# MKE14Z4 register map
Vendor: nxp.com; File version: 1.0
CPU: CM0PLUS r0p0, little endian, no MPU, no FPU, VTOR, 2 interrupt priority bits
Registers are 32-bit, read-write, reset 0x0 unless marked. A register's access mark holds for its fields unless they carry their own. Offsets are from the block's base; [hi:lo] are bit positions; {n}, {i} and the like mark numbered series.

## SIM — System Integration Module
Base 0x40048000; register names take the prefix SIM_
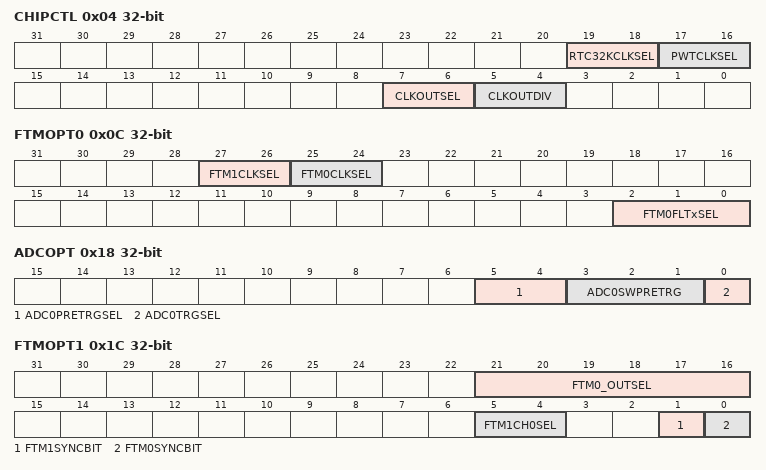
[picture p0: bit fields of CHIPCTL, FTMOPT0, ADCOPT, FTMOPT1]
0x04 CHIPCTL — Chip Control register
  [19:18] RTC32KCLKSEL — RTC 32K clock input select
    0=OSC32K (SOSC 32 kHZ high gain clock); 1=RTC_CLKIN
  [17:16] PWTCLKSEL — PWT clock source select
    0=TCLK0 (PWT alternative clock is from the TCLK0 pin.); 1=TCLK1 (PWT alternative clock is from the TCLK1 pin.); 2=TCLK2 (PWT alternative clock is from the TCLK2 pin.)
  [7:6] CLKOUTSEL — CLKOUT Select
    1=SCGCLKOUT (SCGCLKOUT(SIRC/FIRC/SOSC/LPFLL), see SCG_CLKOUTCNFG register.); 3=LPO (LPO clock (128 kHz))
  [5:4] CLKOUTDIV — CLKOUT divider ratio
    0=DIV1 (Divided by 1); 1=DIV2 (Divided by 2); 2=DIV4 (Divided by 4); 3=DIV8 (Divided by 8)
0x0C FTMOPT0 — FTM Option Register 0
  [27:26] FTM1CLKSEL — FTM1 External Clock Pin Select
    0=TCLK0 (FTM1 external clock driven by TCLK0 pin.); 1=TCLK1 (FTM1 external clock driven by TCLK1 pin.); 2=TCLK2 (FTM1 external clock driven by TCLK2 pin.); 3=NONE (No clock input)
  [25:24] FTM0CLKSEL — FTM0 External Clock Pin Select
    0=TCLK0 (FTM0 external clock driven by TCLK0 pin.); 1=TCLK1 (FTM0 external clock driven by TCLK1 pin.); 2=TCLK2 (FTM0 external clock driven by TCLK2 pin.); 3=NONE (No clock input)
  [2:0] FTM0FLTxSEL — FTM0 Fault x Select
0x18 ADCOPT — ADC Options Register
  [5:4] ADC0PRETRGSEL — ADC0 pre-trigger source select
    0=PDB (PDB output); 1=TRGMUX (TRGMUX output); 2=SOFTWR (ADC0 software pre-trigger)
  [3:1] ADC0SWPRETRG — ADC0 software pre-trigger sources
    0=DISABLED (software pre-trigger disabled); {v}=PRETR{v-4} (software pre-trigger {v-4}) (v=4..7)
  [0] ADC0TRGSEL — ADC0 trigger source select
    0=PDB (PDB output); 1=TRGMUX (TRGMUX output)
0x1C FTMOPT1 — FTM Option Register 1
  [21:16] FTM0_OUTSEL — FTM0 channel modulation select with FTM1_CH1
    0=NONE (No modulation with FTM1_CH1); 1=FTM1CH1 (Modulation with FTM1_CH1)
  [5:4] FTM1CH0SEL — FTM1 CH0 Select
    0=FTM1CH0 (FTM1_CH0 input); 1=CMP0 (CMP0 output)
  [1] FTM1SYNCBIT
    0=NONE (No effect.); 1=FTM1 (Write 1 to assert the TRIG1 input to FTM1. Software must clear this bit to allow other trigger sources to assert.)
  [0] FTM0SYNCBIT
    0=NONE (No effect.); 1=FTM0 (Write 1 to assert the TRIG1 input to FTM0. Software must clear this bit to allow other trigger sources to assert.)
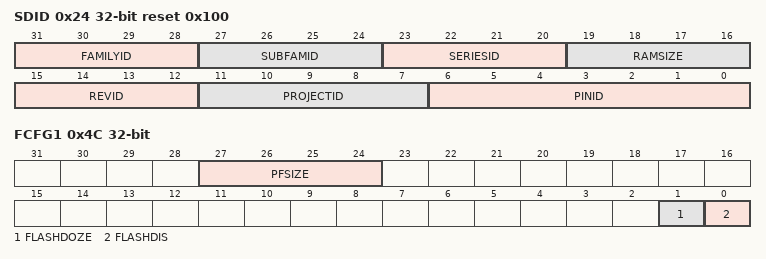
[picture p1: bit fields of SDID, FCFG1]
0x24 SDID ro reset 0x100 (reset mask 0xF80) — System Device Identification Register
  [31:28] FAMILYID — Kinetis E-series Family ID
    1=KE1x Family (Enhanced features)
  [27:24] SUBFAMID — Kinetis E-series Sub-Family ID
  [23:20] SERIESID — Kinetis Series ID
    2=Kinetis E+ series
  [19:16] RAMSIZE
    3=4 KB; 4=8 KB
  [15:12] REVID — Device revision number
  [11:7] PROJECTID
  [6:0] PINID — Pin identification
    4=32-pin; 5=44-pin; 6=48-pin
0x4C FCFG1 (reset mask 0xF0FFFFFF) — Flash Configuration Register 1
  [27:24] PFSIZE ro — Program flash size
    0=SIZE8K (8 KB of program flash memory, 1 KB protection region); 1=SIZE16K (16 KB of program flash memory, 1 KB protection region); 3=SIZE32K (32 KB of program flash memory, 1 KB protection region); 5=SIZE64K (64 KB of program flash memory, 2 KB protection region)
  [1] FLASHDOZE
    0=FLASH_EN (Flash remains enabled during Doze mode); 1=FLASH_DIS (Flash is disabled for the duration of Doze mode)
  [0] FLASHDIS — Flash Disable
    0=FLASH_EN (Flash is enabled); 1=FLASH_DIS (Flash is disabled)
0x50 FCFG2 ro reset 0x7F800000 — Flash Configuration Register 2
  [30:24] MAXADDR0 — Max address block 0
0x54 UIDH ro — Unique Identification Register High
  [31:0] UID127_96 — Unique Identification
0x58 UIDMH ro — Unique Identification Register Mid-High
  [31:0] UID95_64 — Unique Identification
0x5C UIDML ro — Unique Identification Register Mid Low
  [31:0] UID63_32 — Unique Identification
0x60 UIDL ro — Unique Identification Register Low
  [31:0] UID31_0 — Unique Identification
0x6C MISCTRL — Miscellaneous Control register
  [0] SW_TRG — Software Trigger bit to TRGMUX

## Notices in the file
Copyright 2016-2020 NXP
All rights reserved.
SPDX-License-Identifier: BSD-3-Clause
